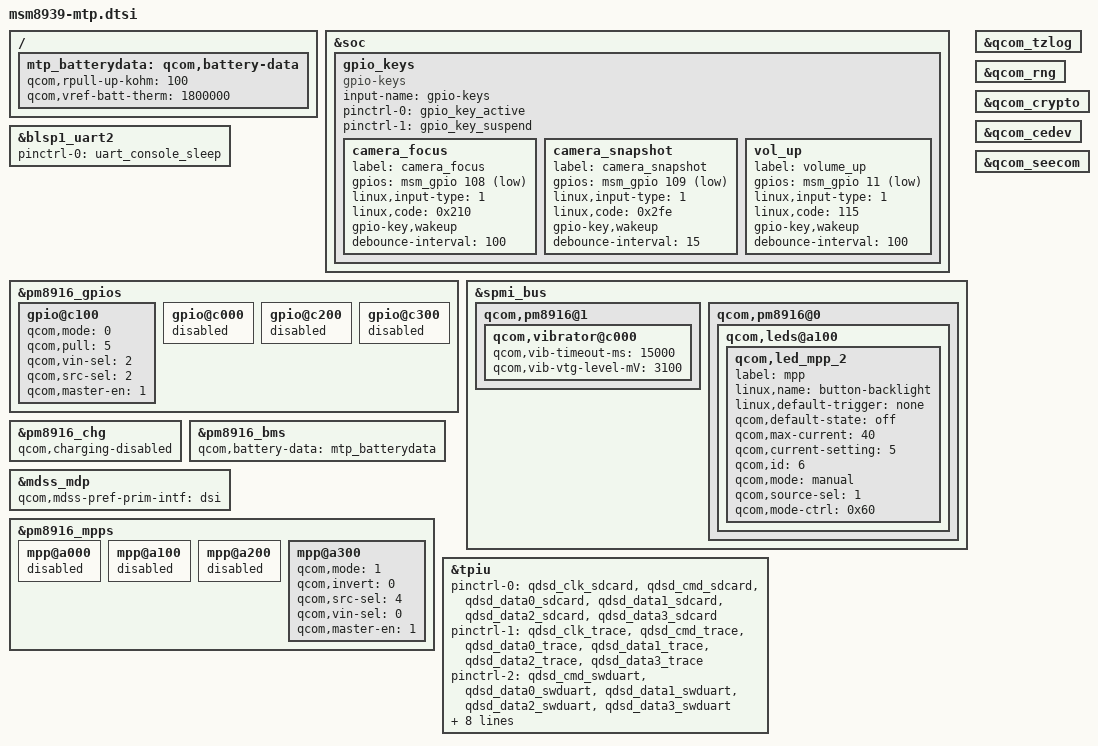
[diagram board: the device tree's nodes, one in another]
/* Copyright (c) 2014-2015, The Linux Foundation. All rights reserved.
 *
 * This program is free software; you can redistribute it and/or modify
 * it under the terms of the GNU General Public License version 2 and
 * only version 2 as published by the Free Software Foundation.
 *
 * This program is distributed in the hope that it will be useful,
 * but WITHOUT ANY WARRANTY; without even the implied warranty of
 * MERCHANTABILITY or FITNESS FOR A PARTICULAR PURPOSE.  See the
 * GNU General Public License for more details.
 */

#include "msm8939-pinctrl.dtsi"
//#include "msm8939-camera-sensor-mtp.dtsi"

&soc {
	gpio_keys {
		compatible = "gpio-keys";
		input-name = "gpio-keys";
		pinctrl-names = "tlmm_gpio_key_active","tlmm_gpio_key_suspend";
		pinctrl-0 = <&gpio_key_active>;
		pinctrl-1 = <&gpio_key_suspend>;

		camera_focus {
			label = "camera_focus";
			gpios = <&msm_gpio 108 0x1>;
			linux,input-type = <1>;
			linux,code = <0x210>;
			gpio-key,wakeup;
			debounce-interval = <100>;
		};

		camera_snapshot {
			label = "camera_snapshot";
			gpios = <&msm_gpio 109 0x1>;
			linux,input-type = <1>;
			linux,code = <0x2fe>;
			gpio-key,wakeup;
			debounce-interval = <15>;
		};

		vol_up {
			label = "volume_up";
			gpios = <&msm_gpio 11 0x1>;
			linux,input-type = <1>;
			linux,code = <115>;
			gpio-key,wakeup;
			debounce-interval = <100>;
		};
	};
};

&blsp1_uart2 {
	status = "ok";
	pinctrl-names = "default";
	pinctrl-0 = <&uart_console_sleep>;
};

&pm8916_gpios {
	gpio@c100 { /* GPIO 2 */
		/* NFC_CLK_REQ */
		qcom,mode = <0>; /* QPNP_PIN_MODE_DIG_IN */
		qcom,pull = <5>; /* QPNP_PIN_PULL_NO */
		qcom,vin-sel = <2>; /* QPNP_PIN_VIN2 */
		qcom,src-sel = <2>; /* QPNP_PIN_SEL_FUNC_1 */
		qcom,master-en = <1>;
	};
};
&spmi_bus {
	qcom,pm8916@1 {
		qcom,vibrator@c000 {
			status = "okay";
			qcom,vib-timeout-ms = <15000>;
			qcom,vib-vtg-level-mV = <3100>;
		};
	};

	qcom,pm8916@0 {
		qcom,leds@a100 {
			status = "okay";
			qcom,led_mpp_2 {
				label = "mpp";
				linux,name = "button-backlight";
				linux,default-trigger = "none";
				qcom,default-state = "off";
				qcom,max-current = <40>;
				qcom,current-setting = <5>;
				qcom,id = <6>;
				qcom,mode = "manual";
				qcom,source-sel = <1>;
				qcom,mode-ctrl = <0x60>;
			};
		};
	};
};

&pm8916_chg {
	status = "ok";
	qcom,charging-disabled;
};

/ {
	mtp_batterydata: qcom,battery-data {
		qcom,rpull-up-kohm = <100>;
		qcom,vref-batt-therm = <1800000>;

		#include "batterydata-palladium.dtsi"
	};
};

&pm8916_bms {
	status = "ok";
	qcom,battery-data = <&mtp_batterydata>;
};

&qcom_tzlog {
	status = "okay";
};

&qcom_rng {
	status = "okay";
};

&qcom_crypto {
	status = "okay";
};

&qcom_cedev {
	status = "okay";
};

&qcom_seecom {
	status = "okay";
};

&mdss_mdp {
	qcom,mdss-pref-prim-intf = "dsi";
};


&pm8916_mpps {
	mpp@a000 { /* MPP 1 */
		/* VDD_PX */
		status = "disabled";
	};

	mpp@a100 { /* MPP 2 */
		/* HR LED */
		status = "disabled";
	};

	mpp@a200 { /* MPP 3 */
		/* VREF DAC */
		status = "disabled";
	};

	mpp@a300 { /* MPP 4 */
		/* Backlight PWM */
		qcom,mode = <1>;		/* Digital output */
		qcom,invert = <0>;		/* Disable invert */
		qcom,src-sel = <4>;		/* DTEST1 */
		qcom,vin-sel = <0>;		/* VPH_PWR */
		qcom,master-en = <1>;		/* Enable MPP */
	};
};

&pm8916_gpios {
	gpio@c000 { /* GPIO 1 */
		/* Battery UICC Alarm */
		status = "disabled";
	};

	gpio@c100 { /* GPIO 2 */
		/* NFC_CLK_REQ */
		qcom,mode = <0>; /* QPNP_PIN_MODE_DIG_IN */
		qcom,pull = <5>; /* QPNP_PIN_PULL_NO */
		qcom,vin-sel = <2>; /* QPNP_PIN_VIN2 */
		qcom,src-sel = <2>; /* QPNP_PIN_SEL_FUNC_1 */
		qcom,master-en = <1>;
	};

	gpio@c200 { /* GPIO 3 */
		/* External regulator control for WTR */
		status = "disabled";
	};

	gpio@c300 { /* GPIO 4 */
		/* External regulator control for APC */
		status = "disabled";
	};
};

/* CoreSight */
&tpiu {
	pinctrl-names = "sdcard", "trace", "swduart",
			"swdtrc", "jtag", "spmi";
	/* NIDnT */
	pinctrl-0 = <&qdsd_clk_sdcard &qdsd_cmd_sdcard
		     &qdsd_data0_sdcard &qdsd_data1_sdcard
		     &qdsd_data2_sdcard &qdsd_data3_sdcard>;
	pinctrl-1 = <&qdsd_clk_trace &qdsd_cmd_trace
		     &qdsd_data0_trace &qdsd_data1_trace
		     &qdsd_data2_trace &qdsd_data3_trace>;
	pinctrl-2 = <&qdsd_cmd_swduart &qdsd_data0_swduart
		     &qdsd_data1_swduart &qdsd_data2_swduart
		     &qdsd_data3_swduart>;
	pinctrl-3 = <&qdsd_clk_swdtrc &qdsd_cmd_swdtrc
		     &qdsd_data0_swdtrc &qdsd_data1_swdtrc
		     &qdsd_data2_swdtrc &qdsd_data3_swdtrc>;
	pinctrl-4 = <&qdsd_cmd_jtag &qdsd_data0_jtag
		     &qdsd_data1_jtag &qdsd_data2_jtag
		     &qdsd_data3_jtag>;
	pinctrl-5 = <&qdsd_clk_spmi &qdsd_cmd_spmi
		     &qdsd_data0_spmi &qdsd_data3_spmi>;
};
